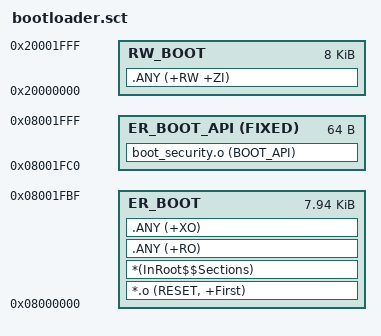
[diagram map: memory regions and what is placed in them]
LR_BOOT 0x08000000 0x00002000 {
  ER_BOOT 0x08000000 0x00001FC0 {
    *.o (RESET, +First)
    *(InRoot$$Sections)
    .ANY (+RO)
    .ANY (+XO)
  }
  ER_BOOT_API 0x08001FC0 FIXED 0x00000040 {
    boot_security.o (BOOT_API)
  }
  RW_BOOT 0x20000000 0x00002000 {
    .ANY (+RW +ZI)
  }
}
